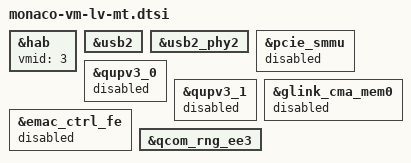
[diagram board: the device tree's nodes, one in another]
&hab {
	vmid = <3>;
};

&usb2 {
	/delete-property/ qcom,host-poweroff-in-pm-suspend;
	/delete-property/ qcom,default-mode-host;
	status = "ok";
};

&usb2_phy2 {
	status = "ok";
};

&pcie_smmu {
	status = "disabled";
};

&qupv3_0 {
	status = "disabled";
};

&qupv3_1 {
	status = "disabled";
};

&glink_cma_mem0 {
	status = "disabled";
};

&emac_ctrl_fe {
	status = "disabled";
};

&qcom_rng_ee3 {
	status = "ok";
};
